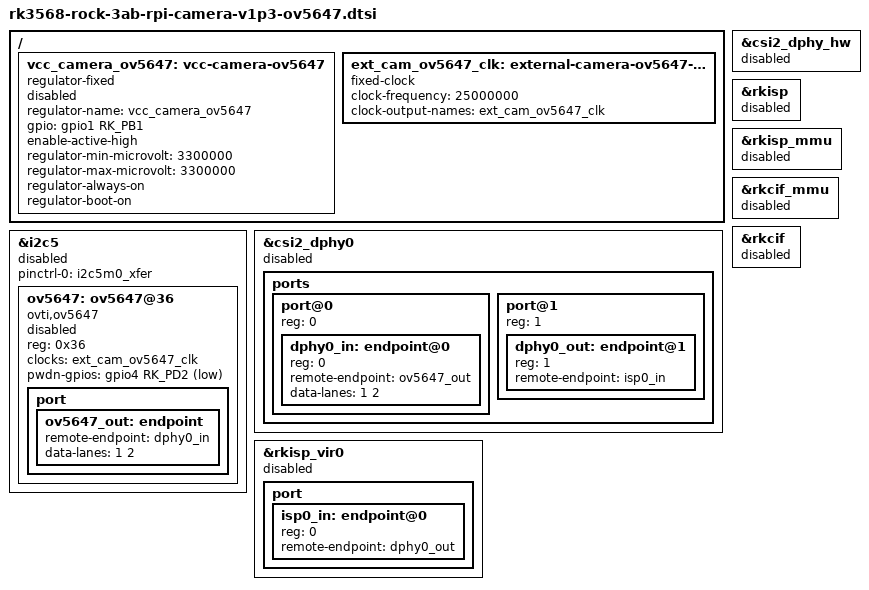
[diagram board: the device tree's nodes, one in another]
// SPDX-License-Identifier: (GPL-2.0+ OR MIT)
/*
 * Copyright (c) 2022 Radxa Limited.
 *
 */

/ {
	vcc_camera_ov5647: vcc-camera-ov5647 {
		status = "disabled";
		compatible = "regulator-fixed";
		regulator-name = "vcc_camera_ov5647";
		gpio = <&gpio1 RK_PB1 GPIO_ACTIVE_HIGH>;
		enable-active-high;
		regulator-min-microvolt = <3300000>;
		regulator-max-microvolt = <3300000>;
		regulator-always-on;
		regulator-boot-on;
	};

	ext_cam_ov5647_clk: external-camera-ov5647-clock {
		compatible = "fixed-clock";
		clock-frequency = <25000000>;
		clock-output-names = "ext_cam_ov5647_clk";
		#clock-cells = <0>;
	};
};

&i2c5 {
	status = "disabled";
	pinctrl-names = "default";
	pinctrl-0 = <&i2c5m0_xfer>;

	ov5647: ov5647@36 {
		status = "disabled";
		compatible = "ovti,ov5647";
		reg = <0x36>;

		clocks = <&ext_cam_ov5647_clk>;
		clock-names = "ext_cam_ov5647_clk";
		pwdn-gpios = <&gpio4 RK_PD2 GPIO_ACTIVE_LOW>;

		port {
			ov5647_out: endpoint {
				remote-endpoint = <&dphy0_in>;
				data-lanes = <1 2>;
			};
		};
	};
};

&csi2_dphy_hw {
	status = "disabled";
};

&csi2_dphy0 {
	status = "disabled";
	/*
	 * dphy1 only used for split mode,
	 * can be used  concurrently  with dphy2
	 * full mode and split mode are mutually exclusive
	 */
	ports {
		#address-cells = <1>;
		#size-cells = <0>;

		port@0 {
			reg = <0>;
			#address-cells = <1>;
			#size-cells = <0>;

			dphy0_in: endpoint@0 {
				reg = <0>;
				remote-endpoint = <&ov5647_out>;
				data-lanes = <1 2>;
			};
		};

		port@1 {
			reg = <1>;
			#address-cells = <1>;
			#size-cells = <0>;

			dphy0_out: endpoint@1 {
				reg = <1>;
				remote-endpoint = <&isp0_in>;
			};
		};
	};
};

&rkisp_vir0 {
	status = "disabled";

	port {
		#address-cells = <1>;
		#size-cells = <0>;

		isp0_in: endpoint@0 {
			reg = <0>;
			remote-endpoint = <&dphy0_out>;
		};
	};
};

&rkisp {
	status = "disabled";
};

&rkisp_mmu {
	status = "disabled";
};

&rkcif_mmu {
	status = "disabled";
};

&rkcif {
	status = "disabled";
};
